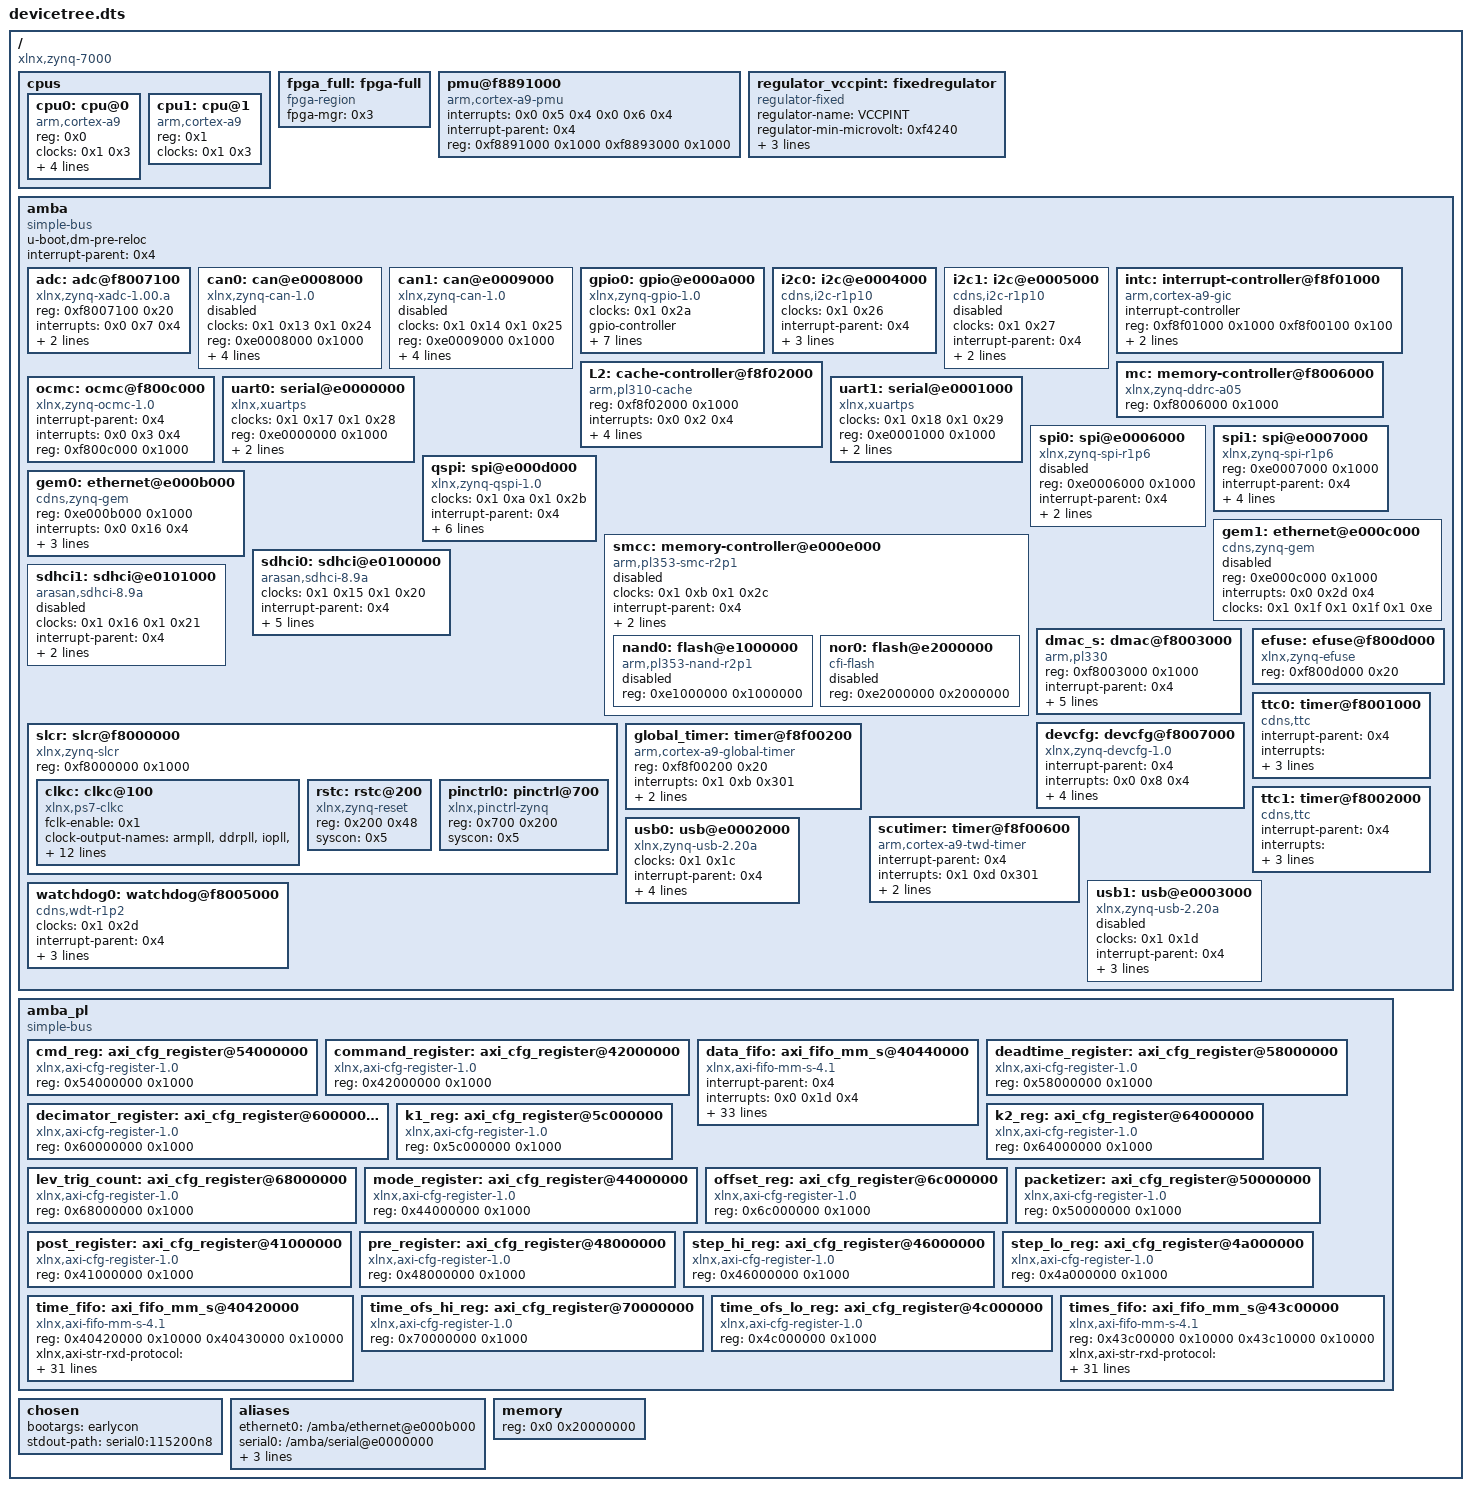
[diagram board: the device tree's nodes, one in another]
/dts-v1/;

/ {
	#address-cells = <0x1>;
	#size-cells = <0x1>;
	compatible = "xlnx,zynq-7000";

	cpus {
		#address-cells = <0x1>;
		#size-cells = <0x0>;

		cpu0: cpu@0 {
			compatible = "arm,cortex-a9";
			device_type = "cpu";
			reg = <0x0>;
			clocks = <0x1 0x3>;
			clock-latency = <0x3e8>;
			cpu0-supply = <0x2>;
			operating-points = <0xa2c2a 0xf4240 0x51615 0xf4240>;
		};

		cpu1: cpu@1 {
			compatible = "arm,cortex-a9";
			device_type = "cpu";
			reg = <0x1>;
			clocks = <0x1 0x3>;
		};
	};

	fpga_full: fpga-full {
		compatible = "fpga-region";
		fpga-mgr = <0x3>;
		#address-cells = <0x1>;
		#size-cells = <0x1>;
		ranges;
	};

	pmu@f8891000 {
		compatible = "arm,cortex-a9-pmu";
		interrupts = <0x0 0x5 0x4 0x0 0x6 0x4>;
		interrupt-parent = <0x4>;
		reg = <0xf8891000 0x1000 0xf8893000 0x1000>;
	};

	regulator_vccpint: fixedregulator {
		compatible = "regulator-fixed";
		regulator-name = "VCCPINT";
		regulator-min-microvolt = <0xf4240>;
		regulator-max-microvolt = <0xf4240>;
		regulator-boot-on;
		regulator-always-on;
		linux,phandle = <0x2>;
		phandle = <0x2>;
	};

	amba: amba {
		u-boot,dm-pre-reloc;
		compatible = "simple-bus";
		#address-cells = <0x1>;
		#size-cells = <0x1>;
		interrupt-parent = <0x4>;
		ranges;

		adc: adc@f8007100 {
			compatible = "xlnx,zynq-xadc-1.00.a";
			reg = <0xf8007100 0x20>;
			interrupts = <0x0 0x7 0x4>;
			interrupt-parent = <0x4>;
			clocks = <0x1 0xc>;
		};

		can0: can@e0008000 {
			compatible = "xlnx,zynq-can-1.0";
			status = "disabled";
			clocks = <0x1 0x13 0x1 0x24>;
			clock-names = "can_clk", "pclk";
			reg = <0xe0008000 0x1000>;
			interrupts = <0x0 0x1c 0x4>;
			interrupt-parent = <0x4>;
			tx-fifo-depth = <0x40>;
			rx-fifo-depth = <0x40>;
		};

		can1: can@e0009000 {
			compatible = "xlnx,zynq-can-1.0";
			status = "disabled";
			clocks = <0x1 0x14 0x1 0x25>;
			clock-names = "can_clk", "pclk";
			reg = <0xe0009000 0x1000>;
			interrupts = <0x0 0x33 0x4>;
			interrupt-parent = <0x4>;
			tx-fifo-depth = <0x40>;
			rx-fifo-depth = <0x40>;
		};

		gpio0: gpio@e000a000 {
			compatible = "xlnx,zynq-gpio-1.0";
			#gpio-cells = <0x2>;
			clocks = <0x1 0x2a>;
			gpio-controller;
			interrupt-controller;
			#interrupt-cells = <0x2>;
			interrupt-parent = <0x4>;
			interrupts = <0x0 0x14 0x4>;
			reg = <0xe000a000 0x1000>;
			emio-gpio-width = <0x40>;
			gpio-mask-high = <0x0>;
			gpio-mask-low = <0x5600>;
			linux,phandle = <0x6>;
			phandle = <0x6>;
		};

		i2c0: i2c@e0004000 {
			compatible = "cdns,i2c-r1p10";
			status = "okay";
			clocks = <0x1 0x26>;
			interrupt-parent = <0x4>;
			interrupts = <0x0 0x19 0x4>;
			reg = <0xe0004000 0x1000>;
			#address-cells = <0x1>;
			#size-cells = <0x0>;
			clock-frequency = <0x61a80>;
		};

		i2c1: i2c@e0005000 {
			compatible = "cdns,i2c-r1p10";
			status = "disabled";
			clocks = <0x1 0x27>;
			interrupt-parent = <0x4>;
			interrupts = <0x0 0x30 0x4>;
			reg = <0xe0005000 0x1000>;
			#address-cells = <0x1>;
			#size-cells = <0x0>;
		};

		intc: interrupt-controller@f8f01000 {
			compatible = "arm,cortex-a9-gic";
			#interrupt-cells = <0x3>;
			interrupt-controller;
			reg = <0xf8f01000 0x1000 0xf8f00100 0x100>;
			num_cpus = <0x2>;
			num_interrupts = <0x60>;
			linux,phandle = <0x4>;
			phandle = <0x4>;
		};

		L2: cache-controller@f8f02000 {
			compatible = "arm,pl310-cache";
			reg = <0xf8f02000 0x1000>;
			interrupts = <0x0 0x2 0x4>;
			arm,data-latency = <0x3 0x2 0x2>;
			arm,tag-latency = <0x2 0x2 0x2>;
			cache-unified;
			cache-level = <0x2>;
		};

		mc: memory-controller@f8006000 {
			compatible = "xlnx,zynq-ddrc-a05";
			reg = <0xf8006000 0x1000>;
		};

		ocmc: ocmc@f800c000 {
			compatible = "xlnx,zynq-ocmc-1.0";
			interrupt-parent = <0x4>;
			interrupts = <0x0 0x3 0x4>;
			reg = <0xf800c000 0x1000>;
		};

		uart0: serial@e0000000 {
			compatible = "xlnx,xuartps", "cdns,uart-r1p8";
			status = "okay";
			clocks = <0x1 0x17 0x1 0x28>;
			clock-names = "uart_clk", "pclk";
			reg = <0xe0000000 0x1000>;
			interrupts = <0x0 0x1b 0x4>;
			device_type = "serial";
			port-number = <0x0>;
		};

		uart1: serial@e0001000 {
			compatible = "xlnx,xuartps", "cdns,uart-r1p8";
			status = "okay";
			clocks = <0x1 0x18 0x1 0x29>;
			clock-names = "uart_clk", "pclk";
			reg = <0xe0001000 0x1000>;
			interrupts = <0x0 0x32 0x4>;
			device_type = "serial";
			port-number = <0x1>;
		};

		spi0: spi@e0006000 {
			compatible = "xlnx,zynq-spi-r1p6";
			reg = <0xe0006000 0x1000>;
			status = "disabled";
			interrupt-parent = <0x4>;
			interrupts = <0x0 0x1a 0x4>;
			clocks = <0x1 0x19 0x1 0x22>;
			clock-names = "ref_clk", "pclk";
			#address-cells = <0x1>;
			#size-cells = <0x0>;
		};

		spi1: spi@e0007000 {
			compatible = "xlnx,zynq-spi-r1p6";
			reg = <0xe0007000 0x1000>;
			status = "okay";
			interrupt-parent = <0x4>;
			interrupts = <0x0 0x31 0x4>;
			clocks = <0x1 0x1a 0x1 0x23>;
			clock-names = "ref_clk", "pclk";
			#address-cells = <0x1>;
			#size-cells = <0x0>;
			is-decoded-cs = <0x0>;
			num-cs = <0x1>;
		};

		qspi: spi@e000d000 {
			clock-names = "ref_clk", "pclk";
			clocks = <0x1 0xa 0x1 0x2b>;
			compatible = "xlnx,zynq-qspi-1.0";
			status = "okay";
			interrupt-parent = <0x4>;
			interrupts = <0x0 0x13 0x4>;
			reg = <0xe000d000 0x1000>;
			#address-cells = <0x1>;
			#size-cells = <0x0>;
			is-dual = <0x0>;
			num-cs = <0x1>;
			spi-rx-bus-width = <0x4>;
			spi-tx-bus-width = <0x4>;
		};

		smcc: memory-controller@e000e000 {
			#address-cells = <0x1>;
			#size-cells = <0x1>;
			status = "disabled";
			clock-names = "memclk", "aclk";
			clocks = <0x1 0xb 0x1 0x2c>;
			compatible = "arm,pl353-smc-r2p1";
			interrupt-parent = <0x4>;
			interrupts = <0x0 0x12 0x4>;
			ranges;
			reg = <0xe000e000 0x1000>;

			nand0: flash@e1000000 {
				status = "disabled";
				compatible = "arm,pl353-nand-r2p1";
				reg = <0xe1000000 0x1000000>;
				#address-cells = <0x1>;
				#size-cells = <0x1>;
			};

			nor0: flash@e2000000 {
				status = "disabled";
				compatible = "cfi-flash";
				reg = <0xe2000000 0x2000000>;
				#address-cells = <0x1>;
				#size-cells = <0x1>;
			};
		};

		gem0: ethernet@e000b000 {
			compatible = "cdns,zynq-gem", "cdns,gem";
			reg = <0xe000b000 0x1000>;
			status = "okay";
			interrupts = <0x0 0x16 0x4>;
			clocks = <0x1 0x1e 0x1 0x1e 0x1 0xd>;
			clock-names = "pclk", "hclk", "tx_clk";
			#address-cells = <0x1>;
			#size-cells = <0x0>;
			phy-mode = "rgmii-id";
			xlnx,ptp-enet-clock = <0x69f6bcb>;
		};

		gem1: ethernet@e000c000 {
			compatible = "cdns,zynq-gem", "cdns,gem";
			reg = <0xe000c000 0x1000>;
			status = "disabled";
			interrupts = <0x0 0x2d 0x4>;
			clocks = <0x1 0x1f 0x1 0x1f 0x1 0xe>;
			clock-names = "pclk", "hclk", "tx_clk";
			#address-cells = <0x1>;
			#size-cells = <0x0>;
		};

		sdhci0: sdhci@e0100000 {
			compatible = "arasan,sdhci-8.9a";
			status = "okay";
			clock-names = "clk_xin", "clk_ahb";
			clocks = <0x1 0x15 0x1 0x20>;
			interrupt-parent = <0x4>;
			interrupts = <0x0 0x18 0x4>;
			reg = <0xe0100000 0x1000>;
			xlnx,has-cd = <0x1>;
			xlnx,has-power = <0x0>;
			xlnx,has-wp = <0x1>;
		};

		sdhci1: sdhci@e0101000 {
			compatible = "arasan,sdhci-8.9a";
			status = "disabled";
			clock-names = "clk_xin", "clk_ahb";
			clocks = <0x1 0x16 0x1 0x21>;
			interrupt-parent = <0x4>;
			interrupts = <0x0 0x2f 0x4>;
			reg = <0xe0101000 0x1000>;
		};

		slcr: slcr@f8000000 {
			#address-cells = <0x1>;
			#size-cells = <0x1>;
			compatible = "xlnx,zynq-slcr", "syscon", "simple-mfd";
			reg = <0xf8000000 0x1000>;
			ranges;
			linux,phandle = <0x5>;
			phandle = <0x5>;

			clkc: clkc@100 {
				#clock-cells = <0x1>;
				compatible = "xlnx,ps7-clkc";
				fclk-enable = <0x1>;
				clock-output-names = "armpll", "ddrpll", "iopll", "cpu_6or4x", "cpu_3or2x", "cpu_2x", "cpu_1x", "ddr2x", "ddr3x", "dci", "lqspi", "smc", "pcap", "gem0", "gem1", "fclk0", "fclk1", "fclk2", "fclk3", "can0", "can1", "sdio0", "sdio1", "uart0", "uart1", "spi0", "spi1", "dma", "usb0_aper", "usb1_aper", "gem0_aper", "gem1_aper", "sdio0_aper", "sdio1_aper", "spi0_aper", "spi1_aper", "can0_aper", "can1_aper", "i2c0_aper", "i2c1_aper", "uart0_aper", "uart1_aper", "gpio_aper", "lqspi_aper", "smc_aper", "swdt", "dbg_trc", "dbg_apb";
				reg = <0x100 0x100>;
				ps-clk-frequency = <0x1fca055>;
				linux,phandle = <0x1>;
				phandle = <0x1>;
			};

			rstc: rstc@200 {
				compatible = "xlnx,zynq-reset";
				reg = <0x200 0x48>;
				#reset-cells = <0x1>;
				syscon = <0x5>;
			};

			pinctrl0: pinctrl@700 {
				compatible = "xlnx,pinctrl-zynq";
				reg = <0x700 0x200>;
				syscon = <0x5>;
			};
		};

		dmac_s: dmac@f8003000 {
			compatible = "arm,pl330", "arm,primecell";
			reg = <0xf8003000 0x1000>;
			interrupt-parent = <0x4>;
			interrupt-names = "abort", "dma0", "dma1", "dma2", "dma3", "dma4", "dma5", "dma6", "dma7";
			interrupts = <0x0 0xd 0x4 0x0 0xe 0x4 0x0 0xf 0x4 0x0 0x10 0x4 0x0 0x11 0x4 0x0 0x28 0x4 0x0 0x29 0x4 0x0 0x2a 0x4 0x0 0x2b 0x4>;
			#dma-cells = <0x1>;
			#dma-channels = <0x8>;
			#dma-requests = <0x4>;
			clocks = <0x1 0x1b>;
			clock-names = "apb_pclk";
		};

		devcfg: devcfg@f8007000 {
			compatible = "xlnx,zynq-devcfg-1.0";
			interrupt-parent = <0x4>;
			interrupts = <0x0 0x8 0x4>;
			reg = <0xf8007000 0x100>;
			clocks = <0x1 0xc 0x1 0xf 0x1 0x10 0x1 0x11 0x1 0x12>;
			clock-names = "ref_clk", "fclk0", "fclk1", "fclk2", "fclk3";
			syscon = <0x5>;
			linux,phandle = <0x3>;
			phandle = <0x3>;
		};

		efuse: efuse@f800d000 {
			compatible = "xlnx,zynq-efuse";
			reg = <0xf800d000 0x20>;
		};

		global_timer: timer@f8f00200 {
			compatible = "arm,cortex-a9-global-timer";
			reg = <0xf8f00200 0x20>;
			interrupts = <0x1 0xb 0x301>;
			interrupt-parent = <0x4>;
			clocks = <0x1 0x4>;
		};

		ttc0: timer@f8001000 {
			interrupt-parent = <0x4>;
			interrupts = <0x0 0xa 0x4 0x0 0xb 0x4 0x0 0xc 0x4>;
			compatible = "cdns,ttc";
			clocks = <0x1 0x6>;
			reg = <0xf8001000 0x1000>;
		};

		ttc1: timer@f8002000 {
			interrupt-parent = <0x4>;
			interrupts = <0x0 0x25 0x4 0x0 0x26 0x4 0x0 0x27 0x4>;
			compatible = "cdns,ttc";
			clocks = <0x1 0x6>;
			reg = <0xf8002000 0x1000>;
		};

		scutimer: timer@f8f00600 {
			interrupt-parent = <0x4>;
			interrupts = <0x1 0xd 0x301>;
			compatible = "arm,cortex-a9-twd-timer";
			reg = <0xf8f00600 0x20>;
			clocks = <0x1 0x4>;
		};

		usb0: usb@e0002000 {
			compatible = "xlnx,zynq-usb-2.20a", "chipidea,usb2";
			status = "okay";
			clocks = <0x1 0x1c>;
			interrupt-parent = <0x4>;
			interrupts = <0x0 0x15 0x4>;
			reg = <0xe0002000 0x1000>;
			phy_type = "ulpi";
			usb-reset = <0x6 0x30 0x0>;
		};

		usb1: usb@e0003000 {
			compatible = "xlnx,zynq-usb-2.20a", "chipidea,usb2";
			status = "disabled";
			clocks = <0x1 0x1d>;
			interrupt-parent = <0x4>;
			interrupts = <0x0 0x2c 0x4>;
			reg = <0xe0003000 0x1000>;
			phy_type = "ulpi";
		};

		watchdog0: watchdog@f8005000 {
			clocks = <0x1 0x2d>;
			compatible = "cdns,wdt-r1p2";
			interrupt-parent = <0x4>;
			interrupts = <0x0 0x9 0x1>;
			reg = <0xf8005000 0x1000>;
			timeout-sec = <0xa>;
		};
	};

	amba_pl: amba_pl {
		#address-cells = <0x1>;
		#size-cells = <0x1>;
		compatible = "simple-bus";
		ranges;

		cmd_reg: axi_cfg_register@54000000 {
			compatible = "xlnx,axi-cfg-register-1.0";
			reg = <0x54000000 0x1000>;
		};

		command_register: axi_cfg_register@42000000 {
			compatible = "xlnx,axi-cfg-register-1.0";
			reg = <0x42000000 0x1000>;
		};

		data_fifo: axi_fifo_mm_s@40440000 {
			compatible = "xlnx,axi-fifo-mm-s-4.1";
			interrupt-parent = <0x4>;
			interrupts = <0x0 0x1d 0x4>;
			reg = <0x40440000 0x10000 0x40450000 0x10000>;
			xlnx,axi-str-rxd-protocol = "XIL_AXI_STREAM_ETH_DATA";
			xlnx,axi-str-rxd-tdata-width = <0x20>;
			xlnx,axi-str-txc-protocol = "XIL_AXI_STREAM_ETH_CTRL";
			xlnx,axi-str-txc-tdata-width = <0x20>;
			xlnx,axi-str-txd-protocol = "XIL_AXI_STREAM_ETH_DATA";
			xlnx,axi-str-txd-tdata-width = <0x20>;
			xlnx,axis-tdest-width = <0x4>;
			xlnx,axis-tid-width = <0x4>;
			xlnx,axis-tuser-width = <0x4>;
			xlnx,data-interface-type = <0x1>;
			xlnx,has-axis-tdest = <0x0>;
			xlnx,has-axis-tid = <0x0>;
			xlnx,has-axis-tkeep = <0x0>;
			xlnx,has-axis-tstrb = <0x0>;
			xlnx,has-axis-tuser = <0x0>;
			xlnx,rx-fifo-depth = <0x4000>;
			xlnx,rx-fifo-pe-threshold = <0x2>;
			xlnx,rx-fifo-pf-threshold = <0x64>;
			xlnx,s-axi-id-width = <0xc>;
			xlnx,s-axi4-data-width = <0x20>;
			xlnx,select-xpm = <0x0>;
			xlnx,tx-fifo-depth = <0x200>;
			xlnx,tx-fifo-pe-threshold = <0x2>;
			xlnx,tx-fifo-pf-threshold = <0x1fb>;
			xlnx,use-rx-cut-through = <0x0>;
			xlnx,use-rx-data = <0x1>;
			xlnx,use-tx-ctrl = <0x0>;
			xlnx,use-tx-cut-through = <0x0>;
			xlnx,use-tx-data = <0x0>;
		};

		deadtime_register: axi_cfg_register@58000000 {
			compatible = "xlnx,axi-cfg-register-1.0";
			reg = <0x58000000 0x1000>;
		};

		decimator_register: axi_cfg_register@60000000 {
			compatible = "xlnx,axi-cfg-register-1.0";
			reg = <0x60000000 0x1000>;
		};

		k1_reg: axi_cfg_register@5c000000 {
			compatible = "xlnx,axi-cfg-register-1.0";
			reg = <0x5c000000 0x1000>;
		};

		k2_reg: axi_cfg_register@64000000 {
			compatible = "xlnx,axi-cfg-register-1.0";
			reg = <0x64000000 0x1000>;
		};

		lev_trig_count: axi_cfg_register@68000000 {
			compatible = "xlnx,axi-cfg-register-1.0";
			reg = <0x68000000 0x1000>;
		};

		mode_register: axi_cfg_register@44000000 {
			compatible = "xlnx,axi-cfg-register-1.0";
			reg = <0x44000000 0x1000>;
		};

		offset_reg: axi_cfg_register@6c000000 {
			compatible = "xlnx,axi-cfg-register-1.0";
			reg = <0x6c000000 0x1000>;
		};

		packetizer: axi_cfg_register@50000000 {
			compatible = "xlnx,axi-cfg-register-1.0";
			reg = <0x50000000 0x1000>;
		};

		post_register: axi_cfg_register@41000000 {
			compatible = "xlnx,axi-cfg-register-1.0";
			reg = <0x41000000 0x1000>;
		};

		pre_register: axi_cfg_register@48000000 {
			compatible = "xlnx,axi-cfg-register-1.0";
			reg = <0x48000000 0x1000>;
		};

		step_hi_reg: axi_cfg_register@46000000 {
			compatible = "xlnx,axi-cfg-register-1.0";
			reg = <0x46000000 0x1000>;
		};

		step_lo_reg: axi_cfg_register@4a000000 {
			compatible = "xlnx,axi-cfg-register-1.0";
			reg = <0x4a000000 0x1000>;
		};

		time_fifo: axi_fifo_mm_s@40420000 {
			compatible = "xlnx,axi-fifo-mm-s-4.1";
			reg = <0x40420000 0x10000 0x40430000 0x10000>;
			xlnx,axi-str-rxd-protocol = "XIL_AXI_STREAM_ETH_DATA";
			xlnx,axi-str-rxd-tdata-width = <0x20>;
			xlnx,axi-str-txc-protocol = "XIL_AXI_STREAM_ETH_CTRL";
			xlnx,axi-str-txc-tdata-width = <0x20>;
			xlnx,axi-str-txd-protocol = "XIL_AXI_STREAM_ETH_DATA";
			xlnx,axi-str-txd-tdata-width = <0x20>;
			xlnx,axis-tdest-width = <0x4>;
			xlnx,axis-tid-width = <0x4>;
			xlnx,axis-tuser-width = <0x4>;
			xlnx,data-interface-type = <0x1>;
			xlnx,has-axis-tdest = <0x0>;
			xlnx,has-axis-tid = <0x0>;
			xlnx,has-axis-tkeep = <0x0>;
			xlnx,has-axis-tstrb = <0x0>;
			xlnx,has-axis-tuser = <0x0>;
			xlnx,rx-fifo-depth = <0x200>;
			xlnx,rx-fifo-pe-threshold = <0x2>;
			xlnx,rx-fifo-pf-threshold = <0x1fb>;
			xlnx,s-axi-id-width = <0xc>;
			xlnx,s-axi4-data-width = <0x20>;
			xlnx,select-xpm = <0x0>;
			xlnx,tx-fifo-depth = <0x200>;
			xlnx,tx-fifo-pe-threshold = <0x2>;
			xlnx,tx-fifo-pf-threshold = <0x1fb>;
			xlnx,use-rx-cut-through = <0x0>;
			xlnx,use-rx-data = <0x1>;
			xlnx,use-tx-ctrl = <0x0>;
			xlnx,use-tx-cut-through = <0x0>;
			xlnx,use-tx-data = <0x0>;
		};

		time_ofs_hi_reg: axi_cfg_register@70000000 {
			compatible = "xlnx,axi-cfg-register-1.0";
			reg = <0x70000000 0x1000>;
		};

		time_ofs_lo_reg: axi_cfg_register@4c000000 {
			compatible = "xlnx,axi-cfg-register-1.0";
			reg = <0x4c000000 0x1000>;
		};

		times_fifo: axi_fifo_mm_s@43c00000 {
			compatible = "xlnx,axi-fifo-mm-s-4.1";
			reg = <0x43c00000 0x10000 0x43c10000 0x10000>;
			xlnx,axi-str-rxd-protocol = "XIL_AXI_STREAM_ETH_DATA";
			xlnx,axi-str-rxd-tdata-width = <0x20>;
			xlnx,axi-str-txc-protocol = "XIL_AXI_STREAM_ETH_CTRL";
			xlnx,axi-str-txc-tdata-width = <0x20>;
			xlnx,axi-str-txd-protocol = "XIL_AXI_STREAM_ETH_DATA";
			xlnx,axi-str-txd-tdata-width = <0x20>;
			xlnx,axis-tdest-width = <0x4>;
			xlnx,axis-tid-width = <0x4>;
			xlnx,axis-tuser-width = <0x4>;
			xlnx,data-interface-type = <0x1>;
			xlnx,has-axis-tdest = <0x0>;
			xlnx,has-axis-tid = <0x0>;
			xlnx,has-axis-tkeep = <0x0>;
			xlnx,has-axis-tstrb = <0x0>;
			xlnx,has-axis-tuser = <0x0>;
			xlnx,rx-fifo-depth = <0x200>;
			xlnx,rx-fifo-pe-threshold = <0x2>;
			xlnx,rx-fifo-pf-threshold = <0x1fb>;
			xlnx,s-axi-id-width = <0xc>;
			xlnx,s-axi4-data-width = <0x20>;
			xlnx,select-xpm = <0x0>;
			xlnx,tx-fifo-depth = <0x200>;
			xlnx,tx-fifo-pe-threshold = <0x2>;
			xlnx,tx-fifo-pf-threshold = <0x1fb>;
			xlnx,use-rx-cut-through = <0x0>;
			xlnx,use-rx-data = <0x1>;
			xlnx,use-tx-ctrl = <0x0>;
			xlnx,use-tx-cut-through = <0x0>;
			xlnx,use-tx-data = <0x0>;
		};
	};

	chosen {
		bootargs = "earlycon";
		stdout-path = "serial0:115200n8";
	};

	aliases {
		ethernet0 = "/amba/ethernet@e000b000";
		serial0 = "/amba/serial@e0000000";
		serial1 = "/amba/serial@e0001000";
		spi0 = "/amba/spi@e000d000";
		spi1 = "/amba/spi@e0007000";
	};

	memory {
		device_type = "memory";
		reg = <0x0 0x20000000>;
	};
};
